AUTOSAR XML (schema 4-2-2)
package /IoHwAbW
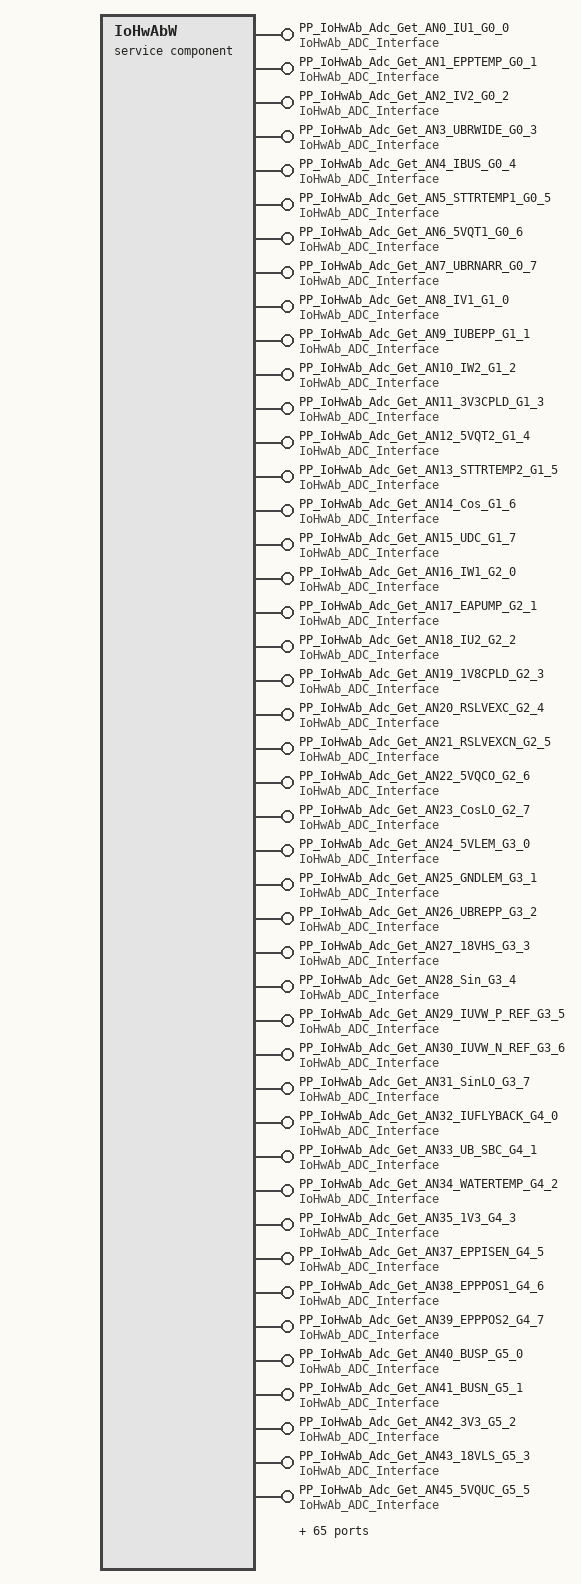
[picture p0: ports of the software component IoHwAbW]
  service sw component type IoHwAbW
    109 x provide port:
      PP_IoHwAb_Adc_Get_AN0_IU1_G0_0: provided-interface=IoHwAb_ADC_Interface
      PP_IoHwAb_Adc_Get_AN1_EPPTEMP_G0_1: provided-interface=IoHwAb_ADC_Interface
      PP_IoHwAb_Adc_Get_AN2_IV2_G0_2: provided-interface=IoHwAb_ADC_Interface
      PP_IoHwAb_Adc_Get_AN3_UBRWIDE_G0_3: provided-interface=IoHwAb_ADC_Interface
      PP_IoHwAb_Adc_Get_AN4_IBUS_G0_4: provided-interface=IoHwAb_ADC_Interface
      PP_IoHwAb_Adc_Get_AN5_STTRTEMP1_G0_5: provided-interface=IoHwAb_ADC_Interface
      PP_IoHwAb_Adc_Get_AN6_5VQT1_G0_6: provided-interface=IoHwAb_ADC_Interface
      PP_IoHwAb_Adc_Get_AN7_UBRNARR_G0_7: provided-interface=IoHwAb_ADC_Interface
      PP_IoHwAb_Adc_Get_AN8_IV1_G1_0: provided-interface=IoHwAb_ADC_Interface
      PP_IoHwAb_Adc_Get_AN9_IUBEPP_G1_1: provided-interface=IoHwAb_ADC_Interface
      PP_IoHwAb_Adc_Get_AN10_IW2_G1_2: provided-interface=IoHwAb_ADC_Interface
      PP_IoHwAb_Adc_Get_AN11_3V3CPLD_G1_3: provided-interface=IoHwAb_ADC_Interface
      PP_IoHwAb_Adc_Get_AN12_5VQT2_G1_4: provided-interface=IoHwAb_ADC_Interface
      PP_IoHwAb_Adc_Get_AN13_STTRTEMP2_G1_5: provided-interface=IoHwAb_ADC_Interface
      PP_IoHwAb_Adc_Get_AN14_Cos_G1_6: provided-interface=IoHwAb_ADC_Interface
      PP_IoHwAb_Adc_Get_AN15_UDC_G1_7: provided-interface=IoHwAb_ADC_Interface
      PP_IoHwAb_Adc_Get_AN16_IW1_G2_0: provided-interface=IoHwAb_ADC_Interface
      PP_IoHwAb_Adc_Get_AN17_EAPUMP_G2_1: provided-interface=IoHwAb_ADC_Interface
      PP_IoHwAb_Adc_Get_AN18_IU2_G2_2: provided-interface=IoHwAb_ADC_Interface
      PP_IoHwAb_Adc_Get_AN19_1V8CPLD_G2_3: provided-interface=IoHwAb_ADC_Interface
      PP_IoHwAb_Adc_Get_AN20_RSLVEXC_G2_4: provided-interface=IoHwAb_ADC_Interface
      PP_IoHwAb_Adc_Get_AN21_RSLVEXCN_G2_5: provided-interface=IoHwAb_ADC_Interface
      PP_IoHwAb_Adc_Get_AN22_5VQCO_G2_6: provided-interface=IoHwAb_ADC_Interface
      PP_IoHwAb_Adc_Get_AN23_CosLO_G2_7: provided-interface=IoHwAb_ADC_Interface
      PP_IoHwAb_Adc_Get_AN24_5VLEM_G3_0: provided-interface=IoHwAb_ADC_Interface
      PP_IoHwAb_Adc_Get_AN25_GNDLEM_G3_1: provided-interface=IoHwAb_ADC_Interface
      PP_IoHwAb_Adc_Get_AN26_UBREPP_G3_2: provided-interface=IoHwAb_ADC_Interface
      PP_IoHwAb_Adc_Get_AN27_18VHS_G3_3: provided-interface=IoHwAb_ADC_Interface
      PP_IoHwAb_Adc_Get_AN28_Sin_G3_4: provided-interface=IoHwAb_ADC_Interface
      PP_IoHwAb_Adc_Get_AN29_IUVW_P_REF_G3_5: provided-interface=IoHwAb_ADC_Interface
      PP_IoHwAb_Adc_Get_AN30_IUVW_N_REF_G3_6: provided-interface=IoHwAb_ADC_Interface
      PP_IoHwAb_Adc_Get_AN31_SinLO_G3_7: provided-interface=IoHwAb_ADC_Interface
      PP_IoHwAb_Adc_Get_AN32_IUFLYBACK_G4_0: provided-interface=IoHwAb_ADC_Interface
      PP_IoHwAb_Adc_Get_AN33_UB_SBC_G4_1: provided-interface=IoHwAb_ADC_Interface
      PP_IoHwAb_Adc_Get_AN34_WATERTEMP_G4_2: provided-interface=IoHwAb_ADC_Interface
      PP_IoHwAb_Adc_Get_AN35_1V3_G4_3: provided-interface=IoHwAb_ADC_Interface
      PP_IoHwAb_Adc_Get_AN37_EPPISEN_G4_5: provided-interface=IoHwAb_ADC_Interface
      PP_IoHwAb_Adc_Get_AN38_EPPPOS1_G4_6: provided-interface=IoHwAb_ADC_Interface
      PP_IoHwAb_Adc_Get_AN39_EPPPOS2_G4_7: provided-interface=IoHwAb_ADC_Interface
      PP_IoHwAb_Adc_Get_AN40_BUSP_G5_0: provided-interface=IoHwAb_ADC_Interface
      PP_IoHwAb_Adc_Get_AN41_BUSN_G5_1: provided-interface=IoHwAb_ADC_Interface
      PP_IoHwAb_Adc_Get_AN42_3V3_G5_2: provided-interface=IoHwAb_ADC_Interface
      PP_IoHwAb_Adc_Get_AN43_18VLS_G5_3: provided-interface=IoHwAb_ADC_Interface
      PP_IoHwAb_Adc_Get_AN45_5VQUC_G5_5: provided-interface=IoHwAb_ADC_Interface
      PP_IoHwAb_Adc_Get_AN46_VDD5_EPP_G5_6: provided-interface=IoHwAb_ADC_Interface
      PP_IoHwAb_Dio_Get_DI_EPPOC_P00_3: provided-interface=IoHwAb_IN_Interface
      PP_IoHwAb_Dio_Get_DI_MOTOROPEN_P01_3: provided-interface=IoHwAb_IN_Interface
      PP_IoHwAb_Dio_Get_DI_SPIERR_P10_1: provided-interface=IoHwAb_IN_Interface
      PP_IoHwAb_Dio_Get_DI_RDYLS_P10_4: provided-interface=IoHwAb_IN_Interface
      PP_IoHwAb_Dio_Get_DI_RDYHS_P11_1: provided-interface=IoHwAb_IN_Interface
      PP_IoHwAb_Dio_Get_DI_NFLTHA_P11_4: provided-interface=IoHwAb_IN_Interface
      PP_IoHwAb_Dio_Get_DI_NFLTHB_P12_1: provided-interface=IoHwAb_IN_Interface
      PP_IoHwAb_Dio_Get_DI_NFLTLA_P13_3: provided-interface=IoHwAb_IN_Interface
      PP_IoHwAb_Dio_Get_DI_NFLTLB_P14_8: provided-interface=IoHwAb_IN_Interface
      PP_IoHwAb_Dio_Get_DI_SBCINT_P20_13: provided-interface=IoHwAb_IN_Interface
      PP_IoHwAb_Dio_Get_DI_IPHAOC_P21_0: provided-interface=IoHwAb_IN_Interface
      PP_IoHwAb_Dio_Get_DI_CPLDRES2_P21_2: provided-interface=IoHwAb_IN_Interface
      PP_IoHwAb_Dio_Get_DI_CPLDRES1_P21_3: provided-interface=IoHwAb_IN_Interface
      PP_IoHwAb_Dio_Get_DI_OPENPROTECT_P21_4: provided-interface=IoHwAb_IN_Interface
      PP_IoHwAb_Dio_Get_DI_KL15_P21_5: provided-interface=IoHwAb_IN_Interface
      PP_IoHwAb_Dio_Get_DI_WAKE_P22_8: provided-interface=IoHwAb_IN_Interface
      PP_IoHwAb_Dio_Get_DI_UDCOV_P22_11: provided-interface=IoHwAb_IN_Interface
      PP_IoHwAb_Dio_Get_DI_CAN0ERR_P23_0: provided-interface=IoHwAb_IN_Interface
      PP_IoHwAb_Dio_Get_DI_PARKP_P23_1: provided-interface=IoHwAb_IN_Interface
      PP_IoHwAb_Dio_Get_CRASH: provided-interface=IoHwAb_IN_Interface
      PP_IoHwAb_Dio_Get_DI_SBCSS1_P32_4: provided-interface=IoHwAb_IN_Interface
      PP_IoHwAb_Dio_Set_DO_ENEPARK_P00_0: provided-interface=IoHwAb_OUT_Interface
      PP_IoHwAb_Dio_Set_DO_FLNAKS_P00_10: provided-interface=IoHwAb_OUT_Interface
      PP_IoHwAb_Dio_Set_DO_ENTemp1_P01_5: provided-interface=IoHwAb_OUT_Interface
      PP_IoHwAb_Dio_Set_DO_ENTemp2_P01_6: provided-interface=IoHwAb_OUT_Interface
      PP_IoHwAb_Dio_Set_DO_ASC_P02_10: provided-interface=IoHwAb_OUT_Interface
      PP_IoHwAb_Dio_Set_DO_ENEFUSE_P02_11: provided-interface=IoHwAb_OUT_Interface
      PP_IoHwAb_Dio_Set_DO_CPLDCLR_P10_0: provided-interface=IoHwAb_OUT_Interface
      PP_IoHwAb_Dio_Set_CTR_ENHS_DR: provided-interface=IoHwAb_OUT_Interface
      PP_IoHwAb_Dio_Set_DO_NRSTHS_P11_7: provided-interface=IoHwAb_OUT_Interface
      PP_IoHwAb_Dio_Set_DO_NRSTLS_P11_12: provided-interface=IoHwAb_OUT_Interface
      PP_IoHwAb_Dio_Set_CTR_ENLS_DR: provided-interface=IoHwAb_OUT_Interface
      PP_IoHwAb_Dio_Set_DO_ENBOOST_P14_7: provided-interface=IoHwAb_OUT_Interface
      PP_IoHwAb_Dio_Set_DO_SBCWDI_P14_9: provided-interface=IoHwAb_OUT_Interface
      PP_IoHwAb_Dio_Get_DO_ENEPPEFUSE_P22_4: provided-interface=IoHwAb_IN_Interface
      PP_IoHwAb_Dio_Set_DO_CAN0EN_P22_7: provided-interface=IoHwAb_OUT_Interface
      PP_IoHwAb_Dio_Set_DO_STBCAN_P23_5: provided-interface=IoHwAb_OUT_Interface
      PP_IoHwAb_Dio_Set_DO_RSLVCEXCN_P32_5: provided-interface=IoHwAb_OUT_Interface
      PP_IoHwAb_Dio_Set_DO_RSLVCEXC_P32_7: provided-interface=IoHwAb_OUT_Interface
      PP_IoHwAb_Dio_Set_DO_SBCERR_P33_8: provided-interface=IoHwAb_OUT_Interface
      PP_IoHwAb_Pwm_SetDutyCycle_DO_PWMEPP1_P00_11: provided-interface=IoHwAb_PWM_SetDutyCycle_Interface
      PP_IoHwAb_Pwm_SetDutyCycle_DO_PWMEPP2_P00_12: provided-interface=IoHwAb_PWM_SetDutyCycle_Interface
      PP_IoHwAb_Pwm_SetPeriod_DutyCycle_DO_PWMHUS_P02_1: provided-interface=IoHwAb_PWM_SetPeriod_DutyCycle_Interface
      PP_IoHwAb_Pwm_SetPeriod_DutyCycle_DO_PWMLUS_P02_2: provided-interface=IoHwAb_PWM_SetPeriod_DutyCycle_Interface
      PP_IoHwAb_Pwm_SetPeriod_DutyCycle_DO_PWMHVS_P02_3: provided-interface=IoHwAb_PWM_SetPeriod_DutyCycle_Interface
      PP_IoHwAb_Pwm_SetPeriod_DutyCycle_DO_PWMLVS_P02_4: provided-interface=IoHwAb_PWM_SetPeriod_DutyCycle_Interface
      PP_IoHwAb_Pwm_SetPeriod_DutyCycle_DO_PWMHWS_P02_5: provided-interface=IoHwAb_PWM_SetPeriod_DutyCycle_Interface
      PP_IoHwAb_Pwm_SetPeriod_DutyCycle_DO_PWMLWS_P02_6: provided-interface=IoHwAb_PWM_SetPeriod_DutyCycle_Interface
      PP_IoHwAb_Pwm_SetPeriod_DutyCycle_DO_CPLDCLK_P02_8: provided-interface=IoHwAb_PWM_SetPeriod_DutyCycle_Interface
      PP_IoHwAb_Pwm_SetPeriod_DutyCycle_DO_18VPWMLEN_P10_2: provided-interface=IoHwAb_PWM_SetPeriod_DutyCycle_Interface
      PP_IoHwAb_Pwm_SetDutyCycle_DO_PWMOCREFP_P11_10: provided-interface=IoHwAb_PWM_SetDutyCycle_Interface
      PP_IoHwAb_Pwm_SetDutyCycle_DO_PWMOCREFN_P11_11: provided-interface=IoHwAb_PWM_SetDutyCycle_Interface
      PP_IoHwAb_Pwm_SetPeriod_DutyCycle_MCU_SZTKT_DR: provided-interface=IoHwAb_PWM_SetPeriod_DutyCycle_Interface
      PP_IoHwAb_Pwm_SetPeriod_DutyCycle_DO_PWMPUMP_P20_3: provided-interface=IoHwAb_PWM_SetPeriod_DutyCycle_Interface
      PP_IoHwAb_Pwm_SetPeriod_DutyCycle_DO_18VPWMHEN_P21_1: provided-interface=IoHwAb_PWM_SetPeriod_DutyCycle_Interface
      PP_IoHwAb_Icu_GetPeriod_DutyCycle_DI_PWMLW_P00_4: provided-interface=IoHwAb_ICU_GetPeriod_DutyCycle_Interface
      PP_IoHwAb_Icu_GetPeriod_DutyCycle_DI_PWMHU_P01_7: provided-interface=IoHwAb_ICU_GetPeriod_DutyCycle_Interface
      PP_IoHwAb_Icu_GetPeriod_DutyCycle_DI_PWMHV_P02_9: provided-interface=IoHwAb_ICU_GetPeriod_DutyCycle_Interface
      PP_IoHwAb_Icu_GetPeriod_DutyCycle_DI_PWMLV_P10_7: provided-interface=IoHwAb_ICU_GetPeriod_DutyCycle_Interface
      PP_IoHwAb_Icu_GetPeriod_DutyCycle_DI_PWMLU_P11_0: provided-interface=IoHwAb_ICU_GetPeriod_DutyCycle_Interface
      PP_IoHwAb_Icu_GetPeriod_DutyCycle_DI_PWMHW_P11_8: provided-interface=IoHwAb_ICU_GetPeriod_DutyCycle_Interface
      PP_IoHwAb_Icu_GetPeriod_DutyCycle_DI_FLYBACKPWM_P13_0: provided-interface=IoHwAb_ICU_GetPeriod_DutyCycle_Interface
      PP_IoHwAb_Icu_GetPeriod_DutyCycle_DI_PWMPUMPFB_P23_4: provided-interface=IoHwAb_ICU_GetPeriod_DutyCycle_Interface
      PP_IoHwAb_Adc_Get_HwVer: provided-interface=IoHwAb_ADC_Interface
    behavior IB_IoHwAbW
      109 x operation invoked event:
        OIE_IoHwAb_ADC_GetPhyVoltage_AN0_IU1_G0_0: start-on-event=IoHwAb_ADC_GetPhyVoltage, operation=PP_IoHwAb_Adc_Get_AN0_IU1_G0_0.IoHwAb_ADC_GetPhyVoltage
        OIE_IoHwAb_ADC_GetPhyVoltage_AN1_EPPTEMP_G0_1: start-on-event=IoHwAb_ADC_GetPhyVoltage, operation=PP_IoHwAb_Adc_Get_AN1_EPPTEMP_G0_1.IoHwAb_ADC_GetPhyVoltage
        OIE_IoHwAb_ADC_GetPhyVoltage_AN2_IV2_G0_2: start-on-event=IoHwAb_ADC_GetPhyVoltage, operation=PP_IoHwAb_Adc_Get_AN2_IV2_G0_2.IoHwAb_ADC_GetPhyVoltage
        OIE_IoHwAb_ADC_GetPhyVoltage_AN3_UBRWIDE_G0_3: start-on-event=IoHwAb_ADC_GetPhyVoltage, operation=PP_IoHwAb_Adc_Get_AN3_UBRWIDE_G0_3.IoHwAb_ADC_GetPhyVoltage
        OIE_IoHwAb_ADC_GetPhyVoltage_AN4_IBUS_G0_4: start-on-event=IoHwAb_ADC_GetPhyVoltage, operation=PP_IoHwAb_Adc_Get_AN4_IBUS_G0_4.IoHwAb_ADC_GetPhyVoltage
        OIE_IoHwAb_ADC_GetPhyVoltage_AN5_STTRTEMP1_G0_5: start-on-event=IoHwAb_ADC_GetPhyVoltage, operation=PP_IoHwAb_Adc_Get_AN5_STTRTEMP1_G0_5.IoHwAb_ADC_GetPhyVoltage
        OIE_IoHwAb_ADC_GetPhyVoltage_AN6_5VQT1_G0_6: start-on-event=IoHwAb_ADC_GetPhyVoltage, operation=PP_IoHwAb_Adc_Get_AN6_5VQT1_G0_6.IoHwAb_ADC_GetPhyVoltage
        OIE_IoHwAb_ADC_GetPhyVoltage_AN7_UBRNARR_G0_7: start-on-event=IoHwAb_ADC_GetPhyVoltage, operation=PP_IoHwAb_Adc_Get_AN7_UBRNARR_G0_7.IoHwAb_ADC_GetPhyVoltage
        OIE_IoHwAb_ADC_GetPhyVoltage_AN8_IV1_G1_0: start-on-event=IoHwAb_ADC_GetPhyVoltage, operation=PP_IoHwAb_Adc_Get_AN8_IV1_G1_0.IoHwAb_ADC_GetPhyVoltage
        OIE_IoHwAb_ADC_GetPhyVoltage_AN9_IUBEPP_G1_1: start-on-event=IoHwAb_ADC_GetPhyVoltage, operation=PP_IoHwAb_Adc_Get_AN9_IUBEPP_G1_1.IoHwAb_ADC_GetPhyVoltage
        OIE_IoHwAb_ADC_GetPhyVoltage_AN10_IW2_G1_2: start-on-event=IoHwAb_ADC_GetPhyVoltage, operation=PP_IoHwAb_Adc_Get_AN10_IW2_G1_2.IoHwAb_ADC_GetPhyVoltage
        OIE_IoHwAb_ADC_GetPhyVoltage_AN11_3V3CPLD_G1_3: start-on-event=IoHwAb_ADC_GetPhyVoltage, operation=PP_IoHwAb_Adc_Get_AN11_3V3CPLD_G1_3.IoHwAb_ADC_GetPhyVoltage
        OIE_IoHwAb_ADC_GetPhyVoltage_AN12_5VQT2_G1_4: start-on-event=IoHwAb_ADC_GetPhyVoltage, operation=PP_IoHwAb_Adc_Get_AN12_5VQT2_G1_4.IoHwAb_ADC_GetPhyVoltage
        OIE_IoHwAb_ADC_GetPhyVoltage_AN13_STTRTEMP2_G1_5: start-on-event=IoHwAb_ADC_GetPhyVoltage, operation=PP_IoHwAb_Adc_Get_AN13_STTRTEMP2_G1_5.IoHwAb_ADC_GetPhyVoltage
        OIE_IoHwAb_ADC_GetPhyVoltage_AN14_Cos_G1_6: start-on-event=IoHwAb_ADC_GetPhyVoltage, operation=PP_IoHwAb_Adc_Get_AN14_Cos_G1_6.IoHwAb_ADC_GetPhyVoltage
        OIE_IoHwAb_ADC_GetPhyVoltage_AN15_UDC_G1_7: start-on-event=IoHwAb_ADC_GetPhyVoltage, operation=PP_IoHwAb_Adc_Get_AN15_UDC_G1_7.IoHwAb_ADC_GetPhyVoltage
        OIE_IoHwAb_ADC_GetPhyVoltage_AN16_IW1_G2_0: start-on-event=IoHwAb_ADC_GetPhyVoltage, operation=PP_IoHwAb_Adc_Get_AN16_IW1_G2_0.IoHwAb_ADC_GetPhyVoltage
        OIE_IoHwAb_ADC_GetPhyVoltage_AN17_EAPUMP_G2_1: start-on-event=IoHwAb_ADC_GetPhyVoltage, operation=PP_IoHwAb_Adc_Get_AN17_EAPUMP_G2_1.IoHwAb_ADC_GetPhyVoltage
        OIE_IoHwAb_ADC_GetPhyVoltage_AN18_IU2_G2_2: start-on-event=IoHwAb_ADC_GetPhyVoltage, operation=PP_IoHwAb_Adc_Get_AN18_IU2_G2_2.IoHwAb_ADC_GetPhyVoltage
        OIE_IoHwAb_ADC_GetPhyVoltage_AN19_1V8CPLD_G2_3: start-on-event=IoHwAb_ADC_GetPhyVoltage, operation=PP_IoHwAb_Adc_Get_AN19_1V8CPLD_G2_3.IoHwAb_ADC_GetPhyVoltage
        OIE_IoHwAb_ADC_GetPhyVoltage_AN20_RSLVEXC_G2_4: start-on-event=IoHwAb_ADC_GetPhyVoltage, operation=PP_IoHwAb_Adc_Get_AN20_RSLVEXC_G2_4.IoHwAb_ADC_GetPhyVoltage
        OIE_IoHwAb_ADC_GetPhyVoltage_AN21_RSLVEXCN_G2_5: start-on-event=IoHwAb_ADC_GetPhyVoltage, operation=PP_IoHwAb_Adc_Get_AN21_RSLVEXCN_G2_5.IoHwAb_ADC_GetPhyVoltage
        OIE_IoHwAb_ADC_GetPhyVoltage_AN22_5VQCO_G2_6: start-on-event=IoHwAb_ADC_GetPhyVoltage, operation=PP_IoHwAb_Adc_Get_AN22_5VQCO_G2_6.IoHwAb_ADC_GetPhyVoltage
        OIE_IoHwAb_ADC_GetPhyVoltage_AN23_CosLO_G2_7: start-on-event=IoHwAb_ADC_GetPhyVoltage, operation=PP_IoHwAb_Adc_Get_AN23_CosLO_G2_7.IoHwAb_ADC_GetPhyVoltage
        OIE_IoHwAb_ADC_GetPhyVoltage_AN24_5VLEM_G3_0: start-on-event=IoHwAb_ADC_GetPhyVoltage, operation=PP_IoHwAb_Adc_Get_AN24_5VLEM_G3_0.IoHwAb_ADC_GetPhyVoltage
        OIE_IoHwAb_ADC_GetPhyVoltage_AN25_GNDLEM_G3_1: start-on-event=IoHwAb_ADC_GetPhyVoltage, operation=PP_IoHwAb_Adc_Get_AN25_GNDLEM_G3_1.IoHwAb_ADC_GetPhyVoltage
        OIE_IoHwAb_ADC_GetPhyVoltage_AN26_UBREPP_G3_2: start-on-event=IoHwAb_ADC_GetPhyVoltage, operation=PP_IoHwAb_Adc_Get_AN26_UBREPP_G3_2.IoHwAb_ADC_GetPhyVoltage
        OIE_IoHwAb_ADC_GetPhyVoltage_AN27_18VHS_G3_3: start-on-event=IoHwAb_ADC_GetPhyVoltage, operation=PP_IoHwAb_Adc_Get_AN27_18VHS_G3_3.IoHwAb_ADC_GetPhyVoltage
        OIE_IoHwAb_ADC_GetPhyVoltage_AN28_Sin_G3_4: start-on-event=IoHwAb_ADC_GetPhyVoltage, operation=PP_IoHwAb_Adc_Get_AN28_Sin_G3_4.IoHwAb_ADC_GetPhyVoltage
        OIE_IoHwAb_ADC_GetPhyVoltage_AN29_IUVW_P_REF_G3_5: start-on-event=IoHwAb_ADC_GetPhyVoltage, operation=PP_IoHwAb_Adc_Get_AN29_IUVW_P_REF_G3_5.IoHwAb_ADC_GetPhyVoltage
        OIE_IoHwAb_ADC_GetPhyVoltage_AN30_IUVW_N_REF_G3_6: start-on-event=IoHwAb_ADC_GetPhyVoltage, operation=PP_IoHwAb_Adc_Get_AN30_IUVW_N_REF_G3_6.IoHwAb_ADC_GetPhyVoltage
        OIE_IoHwAb_ADC_GetPhyVoltage_AN31_SinLO_G3_7: start-on-event=IoHwAb_ADC_GetPhyVoltage, operation=PP_IoHwAb_Adc_Get_AN31_SinLO_G3_7.IoHwAb_ADC_GetPhyVoltage
        OIE_IoHwAb_ADC_GetPhyVoltage_AN32_IUFLYBACK_G4_0: start-on-event=IoHwAb_ADC_GetPhyVoltage, operation=PP_IoHwAb_Adc_Get_AN32_IUFLYBACK_G4_0.IoHwAb_ADC_GetPhyVoltage
        OIE_IoHwAb_ADC_GetPhyVoltage_AN33_UB_SBC_G4_1: start-on-event=IoHwAb_ADC_GetPhyVoltage, operation=PP_IoHwAb_Adc_Get_AN33_UB_SBC_G4_1.IoHwAb_ADC_GetPhyVoltage
        OIE_IoHwAb_ADC_GetPhyVoltage_AN34_WATERTEMP_G4_2: start-on-event=IoHwAb_ADC_GetPhyVoltage, operation=PP_IoHwAb_Adc_Get_AN34_WATERTEMP_G4_2.IoHwAb_ADC_GetPhyVoltage
        OIE_IoHwAb_ADC_GetPhyVoltage_AN35_1V3_G4_3: start-on-event=IoHwAb_ADC_GetPhyVoltage, operation=PP_IoHwAb_Adc_Get_AN35_1V3_G4_3.IoHwAb_ADC_GetPhyVoltage
        OIE_IoHwAb_ADC_GetPhyVoltage_AN37_EPPISEN_G4_5: start-on-event=IoHwAb_ADC_GetPhyVoltage, operation=PP_IoHwAb_Adc_Get_AN37_EPPISEN_G4_5.IoHwAb_ADC_GetPhyVoltage
        OIE_IoHwAb_ADC_GetPhyVoltage_AN38_EPPPOS1_G4_6: start-on-event=IoHwAb_ADC_GetPhyVoltage, operation=PP_IoHwAb_Adc_Get_AN38_EPPPOS1_G4_6.IoHwAb_ADC_GetPhyVoltage
        OIE_IoHwAb_ADC_GetPhyVoltage_AN39_EPPPOS2_G4_7: start-on-event=IoHwAb_ADC_GetPhyVoltage, operation=PP_IoHwAb_Adc_Get_AN39_EPPPOS2_G4_7.IoHwAb_ADC_GetPhyVoltage
        OIE_IoHwAb_ADC_GetPhyVoltage_AN40_BUSP_G5_0: start-on-event=IoHwAb_ADC_GetPhyVoltage, operation=PP_IoHwAb_Adc_Get_AN40_BUSP_G5_0.IoHwAb_ADC_GetPhyVoltage
        OIE_IoHwAb_ADC_GetPhyVoltage_AN41_BUSN_G5_1: start-on-event=IoHwAb_ADC_GetPhyVoltage, operation=PP_IoHwAb_Adc_Get_AN41_BUSN_G5_1.IoHwAb_ADC_GetPhyVoltage
        OIE_IoHwAb_ADC_GetPhyVoltage_AN42_3V3_G5_2: start-on-event=IoHwAb_ADC_GetPhyVoltage, operation=PP_IoHwAb_Adc_Get_AN42_3V3_G5_2.IoHwAb_ADC_GetPhyVoltage
        OIE_IoHwAb_ADC_GetPhyVoltage_AN43_18VLS_G5_3: start-on-event=IoHwAb_ADC_GetPhyVoltage, operation=PP_IoHwAb_Adc_Get_AN43_18VLS_G5_3.IoHwAb_ADC_GetPhyVoltage
        OIE_IoHwAb_ADC_GetPhyVoltage_AN45_5VQUC_G5_5: start-on-event=IoHwAb_ADC_GetPhyVoltage, operation=PP_IoHwAb_Adc_Get_AN45_5VQUC_G5_5.IoHwAb_ADC_GetPhyVoltage
        OIE_IoHwAb_ADC_GetPhyVoltage_AN46_VDD5_EPP_G5_6: start-on-event=IoHwAb_ADC_GetPhyVoltage, operation=PP_IoHwAb_Adc_Get_AN46_VDD5_EPP_G5_6.IoHwAb_ADC_GetPhyVoltage
        OIE_IoHwAb_DIO_Get_DI_EPPOC_P00_3: start-on-event=IoHwAb_DIO_Get, operation=PP_IoHwAb_Dio_Get_DI_EPPOC_P00_3.IoHwAb_DIO_Get
        OIE_IoHwAb_DIO_Get_DI_MOTOROPEN_P01_3: start-on-event=IoHwAb_DIO_Get, operation=PP_IoHwAb_Dio_Get_DI_MOTOROPEN_P01_3.IoHwAb_DIO_Get
        OIE_IoHwAb_DIO_Get_DI_SPIERR_P10_1: start-on-event=IoHwAb_DIO_Get, operation=PP_IoHwAb_Dio_Get_DI_SPIERR_P10_1.IoHwAb_DIO_Get
        OIE_IoHwAb_DIO_Get_DI_RDYLS_P10_4: start-on-event=IoHwAb_DIO_Get, operation=PP_IoHwAb_Dio_Get_DI_RDYLS_P10_4.IoHwAb_DIO_Get
        OIE_IoHwAb_DIO_Get_DI_RDYHS_P11_1: start-on-event=IoHwAb_DIO_Get, operation=PP_IoHwAb_Dio_Get_DI_RDYHS_P11_1.IoHwAb_DIO_Get
        OIE_IoHwAb_DIO_Get_DI_NFLTHA_P11_4: start-on-event=IoHwAb_DIO_Get, operation=PP_IoHwAb_Dio_Get_DI_NFLTHA_P11_4.IoHwAb_DIO_Get
        OIE_IoHwAb_DIO_Get_DI_NFLTHB_P12_1: start-on-event=IoHwAb_DIO_Get, operation=PP_IoHwAb_Dio_Get_DI_NFLTHB_P12_1.IoHwAb_DIO_Get
        OIE_IoHwAb_DIO_Get_DI_NFLTLA_P13_3: start-on-event=IoHwAb_DIO_Get, operation=PP_IoHwAb_Dio_Get_DI_NFLTLA_P13_3.IoHwAb_DIO_Get
        OIE_IoHwAb_DIO_Get_DI_NFLTLB_P14_8: start-on-event=IoHwAb_DIO_Get, operation=PP_IoHwAb_Dio_Get_DI_NFLTLB_P14_8.IoHwAb_DIO_Get
        OIE_IoHwAb_DIO_Get_DI_SBCINT_P20_13: start-on-event=IoHwAb_DIO_Get, operation=PP_IoHwAb_Dio_Get_DI_SBCINT_P20_13.IoHwAb_DIO_Get
        OIE_IoHwAb_DIO_Get_DI_IPHAOC_P21_0: start-on-event=IoHwAb_DIO_Get, operation=PP_IoHwAb_Dio_Get_DI_IPHAOC_P21_0.IoHwAb_DIO_Get
        OIE_IoHwAb_DIO_Get_DI_CPLDRES2_P21_2: start-on-event=IoHwAb_DIO_Get, operation=PP_IoHwAb_Dio_Get_DI_CPLDRES2_P21_2.IoHwAb_DIO_Get
        OIE_IoHwAb_DIO_Get_DI_CPLDRES1_P21_3: start-on-event=IoHwAb_DIO_Get, operation=PP_IoHwAb_Dio_Get_DI_CPLDRES1_P21_3.IoHwAb_DIO_Get
        OIE_IoHwAb_DIO_Get_DI_OPENPROTECT_P21_4: start-on-event=IoHwAb_DIO_Get, operation=PP_IoHwAb_Dio_Get_DI_OPENPROTECT_P21_4.IoHwAb_DIO_Get
        OIE_IoHwAb_DIO_Get_DI_KL15_P21_5: start-on-event=IoHwAb_DIO_Get, operation=PP_IoHwAb_Dio_Get_DI_KL15_P21_5.IoHwAb_DIO_Get
        OIE_IoHwAb_DIO_Get_DI_WAKE_P22_8: start-on-event=IoHwAb_DIO_Get, operation=PP_IoHwAb_Dio_Get_DI_WAKE_P22_8.IoHwAb_DIO_Get
        OIE_IoHwAb_DIO_Get_DI_UDCOV_P22_11: start-on-event=IoHwAb_DIO_Get, operation=PP_IoHwAb_Dio_Get_DI_UDCOV_P22_11.IoHwAb_DIO_Get
        OIE_IoHwAb_DIO_Get_DI_CAN0ERR_P23_0: start-on-event=IoHwAb_DIO_Get, operation=PP_IoHwAb_Dio_Get_DI_CAN0ERR_P23_0.IoHwAb_DIO_Get
        OIE_IoHwAb_DIO_Get_DI_PARKP_P23_1: start-on-event=IoHwAb_DIO_Get, operation=PP_IoHwAb_Dio_Get_DI_PARKP_P23_1.IoHwAb_DIO_Get
        OIE_IoHwAb_DIO_Get_CRASH: start-on-event=IoHwAb_DIO_Get, operation=PP_IoHwAb_Dio_Get_CRASH.IoHwAb_DIO_Get
        OIE_IoHwAb_DIO_Get_DI_SBCSS1_P32_4: start-on-event=IoHwAb_DIO_Get, operation=PP_IoHwAb_Dio_Get_DI_SBCSS1_P32_4.IoHwAb_DIO_Get
        OIE_IoHwAb_DIO_Set_DO_ENEPARK_P00_0: start-on-event=IoHwAb_DIO_Set, operation=PP_IoHwAb_Dio_Set_DO_ENEPARK_P00_0.IoHwAb_DIO_Set
        OIE_IoHwAb_DIO_Set_DO_FLNAKS_P00_10: start-on-event=IoHwAb_DIO_Set, operation=PP_IoHwAb_Dio_Set_DO_FLNAKS_P00_10.IoHwAb_DIO_Set
        OIE_IoHwAb_DIO_Set_DO_ENTemp1_P01_5: start-on-event=IoHwAb_DIO_Set, operation=PP_IoHwAb_Dio_Set_DO_ENTemp1_P01_5.IoHwAb_DIO_Set
        OIE_IoHwAb_DIO_Set_DO_ENTemp2_P01_6: start-on-event=IoHwAb_DIO_Set, operation=PP_IoHwAb_Dio_Set_DO_ENTemp2_P01_6.IoHwAb_DIO_Set
        OIE_IoHwAb_DIO_Set_DO_ASC_P02_10: start-on-event=IoHwAb_DIO_Set, operation=PP_IoHwAb_Dio_Set_DO_ASC_P02_10.IoHwAb_DIO_Set
        OIE_IoHwAb_DIO_Set_DO_ENEFUSE_P02_11: start-on-event=IoHwAb_DIO_Set, operation=PP_IoHwAb_Dio_Set_DO_ENEFUSE_P02_11.IoHwAb_DIO_Set
        OIE_IoHwAb_DIO_Set_DO_CPLDCLR_P10_0: start-on-event=IoHwAb_DIO_Set, operation=PP_IoHwAb_Dio_Set_DO_CPLDCLR_P10_0.IoHwAb_DIO_Set
        OIE_IoHwAb_DIO_Set_CTR_ENHS_DR: start-on-event=IoHwAb_DIO_Set, operation=PP_IoHwAb_Dio_Set_CTR_ENHS_DR.IoHwAb_DIO_Set
        OIE_IoHwAb_DIO_Set_DO_NRSTHS_P11_7: start-on-event=IoHwAb_DIO_Set, operation=PP_IoHwAb_Dio_Set_DO_NRSTHS_P11_7.IoHwAb_DIO_Set
        OIE_IoHwAb_DIO_Set_DO_NRSTLS_P11_12: start-on-event=IoHwAb_DIO_Set, operation=PP_IoHwAb_Dio_Set_DO_NRSTLS_P11_12.IoHwAb_DIO_Set
        OIE_IoHwAb_DIO_Set_CTR_ENLS_DR: start-on-event=IoHwAb_DIO_Set, operation=PP_IoHwAb_Dio_Set_CTR_ENLS_DR.IoHwAb_DIO_Set
        OIE_IoHwAb_DIO_Set_DO_ENBOOST_P14_7: start-on-event=IoHwAb_DIO_Set, operation=PP_IoHwAb_Dio_Set_DO_ENBOOST_P14_7.IoHwAb_DIO_Set
        OIE_IoHwAb_DIO_Set_DO_SBCWDI_P14_9: start-on-event=IoHwAb_DIO_Set, operation=PP_IoHwAb_Dio_Set_DO_SBCWDI_P14_9.IoHwAb_DIO_Set
        OIE_IoHwAb_DIO_Set_DO_CAN0EN_P22_7: start-on-event=IoHwAb_DIO_Set, operation=PP_IoHwAb_Dio_Set_DO_CAN0EN_P22_7.IoHwAb_DIO_Set
        OIE_IoHwAb_DIO_Set_DO_STBCAN_P23_5: start-on-event=IoHwAb_DIO_Set, operation=PP_IoHwAb_Dio_Set_DO_STBCAN_P23_5.IoHwAb_DIO_Set
        OIE_IoHwAb_DIO_Set_DO_RSLVCEXCN_P32_5: start-on-event=IoHwAb_DIO_Set, operation=PP_IoHwAb_Dio_Set_DO_RSLVCEXCN_P32_5.IoHwAb_DIO_Set
        OIE_IoHwAb_DIO_Set_DO_RSLVCEXC_P32_7: start-on-event=IoHwAb_DIO_Set, operation=PP_IoHwAb_Dio_Set_DO_RSLVCEXC_P32_7.IoHwAb_DIO_Set
        OIE_IoHwAb_DIO_Set_DO_SBCERR_P33_8: start-on-event=IoHwAb_DIO_Set, operation=PP_IoHwAb_Dio_Set_DO_SBCERR_P33_8.IoHwAb_DIO_Set
        OIE_IoHwAb_PWM_SetDutyCycle_DO_PWMEPP1_P00_11: start-on-event=IoHwAb_PWM_SetDutyCycle, operation=PP_IoHwAb_Pwm_SetDutyCycle_DO_PWMEPP1_P00_11.IoHwAb_PWM_SetDutyCycle
        OIE_IoHwAb_PWM_SetDutyCycle_DO_PWMEPP2_P00_12: start-on-event=IoHwAb_PWM_SetDutyCycle, operation=PP_IoHwAb_Pwm_SetDutyCycle_DO_PWMEPP2_P00_12.IoHwAb_PWM_SetDutyCycle
        OIE_IoHwAb_PWM_SetPeriod_DutyCycle_DO_PWMHUS_P02_1: start-on-event=IoHwAb_PWM_SetPeriod_DutyCycle, operation=PP_IoHwAb_Pwm_SetPeriod_DutyCycle_DO_PWMHUS_P02_1.IoHwAb_PWM_SetPeriod_DutyCycle
        OIE_IoHwAb_PWM_SetPeriod_DutyCycle_DO_PWMLUS_P02_2: start-on-event=IoHwAb_PWM_SetPeriod_DutyCycle, operation=PP_IoHwAb_Pwm_SetPeriod_DutyCycle_DO_PWMLUS_P02_2.IoHwAb_PWM_SetPeriod_DutyCycle
        OIE_IoHwAb_PWM_SetPeriod_DutyCycle_DO_PWMHVS_P02_3: start-on-event=IoHwAb_PWM_SetPeriod_DutyCycle, operation=PP_IoHwAb_Pwm_SetPeriod_DutyCycle_DO_PWMHVS_P02_3.IoHwAb_PWM_SetPeriod_DutyCycle
        OIE_IoHwAb_PWM_SetPeriod_DutyCycle_DO_PWMLVS_P02_4: start-on-event=IoHwAb_PWM_SetPeriod_DutyCycle, operation=PP_IoHwAb_Pwm_SetPeriod_DutyCycle_DO_PWMLVS_P02_4.IoHwAb_PWM_SetPeriod_DutyCycle
        OIE_IoHwAb_PWM_SetPeriod_DutyCycle_DO_PWMHWS_P02_5: start-on-event=IoHwAb_PWM_SetPeriod_DutyCycle, operation=PP_IoHwAb_Pwm_SetPeriod_DutyCycle_DO_PWMHWS_P02_5.IoHwAb_PWM_SetPeriod_DutyCycle
        OIE_IoHwAb_PWM_SetPeriod_DutyCycle_DO_PWMLWS_P02_6: start-on-event=IoHwAb_PWM_SetPeriod_DutyCycle, operation=PP_IoHwAb_Pwm_SetPeriod_DutyCycle_DO_PWMLWS_P02_6.IoHwAb_PWM_SetPeriod_DutyCycle
        OIE_IoHwAb_PWM_SetPeriod_DutyCycle_DO_CPLDCLK_P02_8: start-on-event=IoHwAb_PWM_SetPeriod_DutyCycle, operation=PP_IoHwAb_Pwm_SetPeriod_DutyCycle_DO_CPLDCLK_P02_8.IoHwAb_PWM_SetPeriod_DutyCycle
        OIE_IoHwAb_PWM_SetPeriod_DutyCycle_DO_18VPWMLEN_P10_2: start-on-event=IoHwAb_PWM_SetPeriod_DutyCycle, operation=PP_IoHwAb_Pwm_SetPeriod_DutyCycle_DO_18VPWMLEN_P10_2.IoHwAb_PWM_SetPeriod_DutyCycle
        OIE_IoHwAb_PWM_SetDutyCycle_DO_PWMOCREFP_P11_10: start-on-event=IoHwAb_PWM_SetDutyCycle, operation=PP_IoHwAb_Pwm_SetDutyCycle_DO_PWMOCREFP_P11_10.IoHwAb_PWM_SetDutyCycle
        OIE_IoHwAb_PWM_SetDutyCycle_DO_PWMOCREFN_P11_11: start-on-event=IoHwAb_PWM_SetDutyCycle, operation=PP_IoHwAb_Pwm_SetDutyCycle_DO_PWMOCREFN_P11_11.IoHwAb_PWM_SetDutyCycle
        OIE_IoHwAb_PWM_SetPeriod_DutyCycle_MCU_SZTKT_DR: start-on-event=IoHwAb_PWM_SetPeriod_DutyCycle, operation=PP_IoHwAb_Pwm_SetPeriod_DutyCycle_MCU_SZTKT_DR.IoHwAb_PWM_SetPeriod_DutyCycle
        OIE_IoHwAb_PWM_SetPeriod_DutyCycle_DO_PWMPUMP_P20_3: start-on-event=IoHwAb_PWM_SetPeriod_DutyCycle, operation=PP_IoHwAb_Pwm_SetPeriod_DutyCycle_DO_PWMPUMP_P20_3.IoHwAb_PWM_SetPeriod_DutyCycle
        OIE_IoHwAb_PWM_SetPeriod_DutyCycle_DO_18VPWMHEN_P21_1: start-on-event=IoHwAb_PWM_SetPeriod_DutyCycle, operation=PP_IoHwAb_Pwm_SetPeriod_DutyCycle_DO_18VPWMHEN_P21_1.IoHwAb_PWM_SetPeriod_DutyCycle
        OIE_IoHwAb_ICU_GetPeriod_DutyCycle_DI_PWMLW_P00_4: start-on-event=IoHwAb_ICU_GetPeriod_DutyCycle, operation=PP_IoHwAb_Icu_GetPeriod_DutyCycle_DI_PWMLW_P00_4.IoHwAb_ICU_GetPeriod_DutyCycle
        OIE_IoHwAb_ICU_GetPeriod_DutyCycle_DI_PWMHU_P01_7: start-on-event=IoHwAb_ICU_GetPeriod_DutyCycle, operation=PP_IoHwAb_Icu_GetPeriod_DutyCycle_DI_PWMHU_P01_7.IoHwAb_ICU_GetPeriod_DutyCycle
        OIE_IoHwAb_ICU_GetPeriod_DutyCycle_DI_PWMHV_P02_9: start-on-event=IoHwAb_ICU_GetPeriod_DutyCycle, operation=PP_IoHwAb_Icu_GetPeriod_DutyCycle_DI_PWMHV_P02_9.IoHwAb_ICU_GetPeriod_DutyCycle
        OIE_IoHwAb_ICU_GetPeriod_DutyCycle_DI_PWMLV_P10_7: start-on-event=IoHwAb_ICU_GetPeriod_DutyCycle, operation=PP_IoHwAb_Icu_GetPeriod_DutyCycle_DI_PWMLV_P10_7.IoHwAb_ICU_GetPeriod_DutyCycle
        OIE_IoHwAb_ICU_GetPeriod_DutyCycle_DI_PWMLU_P11_0: start-on-event=IoHwAb_ICU_GetPeriod_DutyCycle, operation=PP_IoHwAb_Icu_GetPeriod_DutyCycle_DI_PWMLU_P11_0.IoHwAb_ICU_GetPeriod_DutyCycle
        OIE_IoHwAb_ICU_GetPeriod_DutyCycle_DI_PWMHW_P11_8: start-on-event=IoHwAb_ICU_GetPeriod_DutyCycle, operation=PP_IoHwAb_Icu_GetPeriod_DutyCycle_DI_PWMHW_P11_8.IoHwAb_ICU_GetPeriod_DutyCycle
        OIE_IoHwAb_ICU_GetPeriod_DutyCycle_DI_FLYBACKPWM_P13_0: start-on-event=IoHwAb_ICU_GetPeriod_DutyCycle, operation=PP_IoHwAb_Icu_GetPeriod_DutyCycle_DI_FLYBACKPWM_P13_0.IoHwAb_ICU_GetPeriod_DutyCycle
        OIE_IoHwAb_ICU_GetPeriod_DutyCycle_DI_PWMPUMPFB_P23_4: start-on-event=IoHwAb_ICU_GetPeriod_DutyCycle, operation=PP_IoHwAb_Icu_GetPeriod_DutyCycle_DI_PWMPUMPFB_P23_4.IoHwAb_ICU_GetPeriod_DutyCycle
        OIE_IoHwAb_Adc_Get_HwVer: start-on-event=IoHwAb_ADC_GetPhyVoltage, operation=PP_IoHwAb_Adc_Get_HwVer.IoHwAb_ADC_GetPhyVoltage
        OIE_IoHwAb_Dio_Get_DO_ENEPPEFUSE_P22_4: start-on-event=IoHwAb_DIO_Get, operation=PP_IoHwAb_Dio_Get_DO_ENEPPEFUSE_P22_4.IoHwAb_DIO_Get
      6 x runnable:
        IoHwAb_DIO_Set
        IoHwAb_DIO_Get
        IoHwAb_PWM_SetDutyCycle
        IoHwAb_PWM_SetPeriod_DutyCycle
        IoHwAb_ADC_GetPhyVoltage
        IoHwAb_ICU_GetPeriod_DutyCycle
